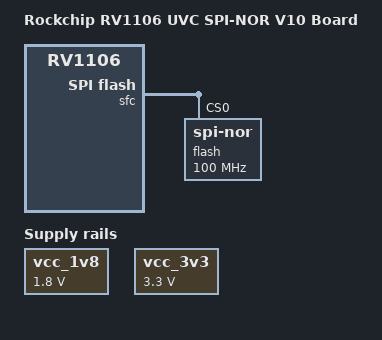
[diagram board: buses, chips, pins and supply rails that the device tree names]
// SPDX-License-Identifier: (GPL-2.0+ OR MIT)
/*
 * Copyright (c) 2022 Rockchip Electronics Co., Ltd.
 */

/dts-v1/;

#include "rv1106.dtsi"
#include "rv1106-uvc-demo.dtsi"

/ {
	model = "Rockchip RV1106 UVC SPI-NOR V10 Board";
	compatible = "rockchip,rv1106-uvc-nor-demo", "rockchip,rv1106";

	chosen {
		bootargs = "earlycon=uart8250,mmio32,0xff4c0000 console=ttyFIQ0 rootwait snd_soc_core.prealloc_buffer_size_kbytes=16";
	};

	vcc_1v8: vcc-1v8 {
		compatible = "regulator-fixed";
		regulator-name = "vcc_1v8";
		regulator-always-on;
		regulator-boot-on;
		regulator-min-microvolt = <1800000>;
		regulator-max-microvolt = <1800000>;
	};

	vcc_3v3: vcc-3v3 {
		compatible = "regulator-fixed";
		regulator-name = "vcc_3v3";
		regulator-always-on;
		regulator-boot-on;
		regulator-min-microvolt = <3300000>;
		regulator-max-microvolt = <3300000>;
	};
};

&emmc {
	status = "disabled";
};

&sfc {
	status = "okay";

	flash@0 {
		compatible = "jedec,spi-nor";
		reg = <0>;
		spi-max-frequency = <100000000>;
		spi-rx-bus-width = <4>;
		spi-tx-bus-width = <1>;
	};
};
